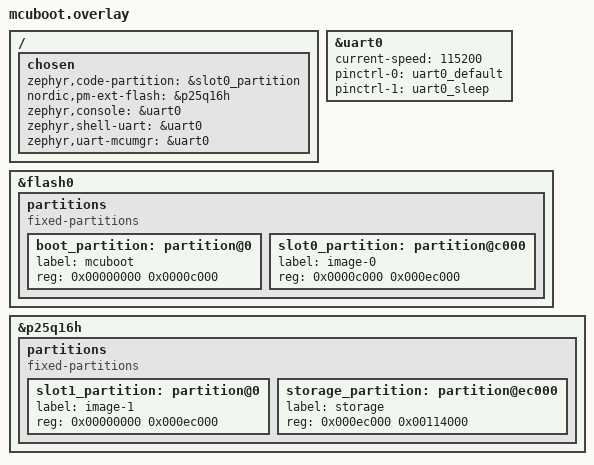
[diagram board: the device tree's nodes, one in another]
/*
 * Copyright (c) 2025 Golioth, Inc.
 *
 * SPDX-License-Identifier: Apache-2.0
 */

/ {
	chosen {
		zephyr,code-partition = &slot0_partition;
		nordic,pm-ext-flash = &p25q16h;
		zephyr,console = &uart0;
        zephyr,shell-uart = &uart0;
        zephyr,uart-mcumgr = &uart0;
	};
};

&uart0 {
	status = "okay";
	current-speed = <115200>;
	pinctrl-0 = <&uart0_default>;
	pinctrl-1 = <&uart0_sleep>;
	pinctrl-names = "default", "sleep";
};

&flash0 {
	/delete-node/ partitions;

	partitions {
		compatible = "fixed-partitions";
		#address-cells = <1>;
		#size-cells = <1>;

		boot_partition: partition@0 {
			label = "mcuboot";
			reg = <0x00000000 0x0000c000>;
		};
		slot0_partition: partition@c000 {
			label = "image-0";
			reg = <0x0000c000 0x000ec000>;
		};
	};
};

&p25q16h {
	status = "okay";
	/delete-property/ zephyr,flash-res-name;

	/delete-node/ partitions;

	partitions {
		compatible = "fixed-partitions";
		#address-cells = <1>;
		#size-cells = <1>;

		slot1_partition: partition@0 {
			label = "image-1";
			reg = <0x00000000 0x000ec000>;
		};

		storage_partition: partition@ec000 {
			label = "storage";
			reg = <0x000ec000 0x00114000>;
		};
	};
};
